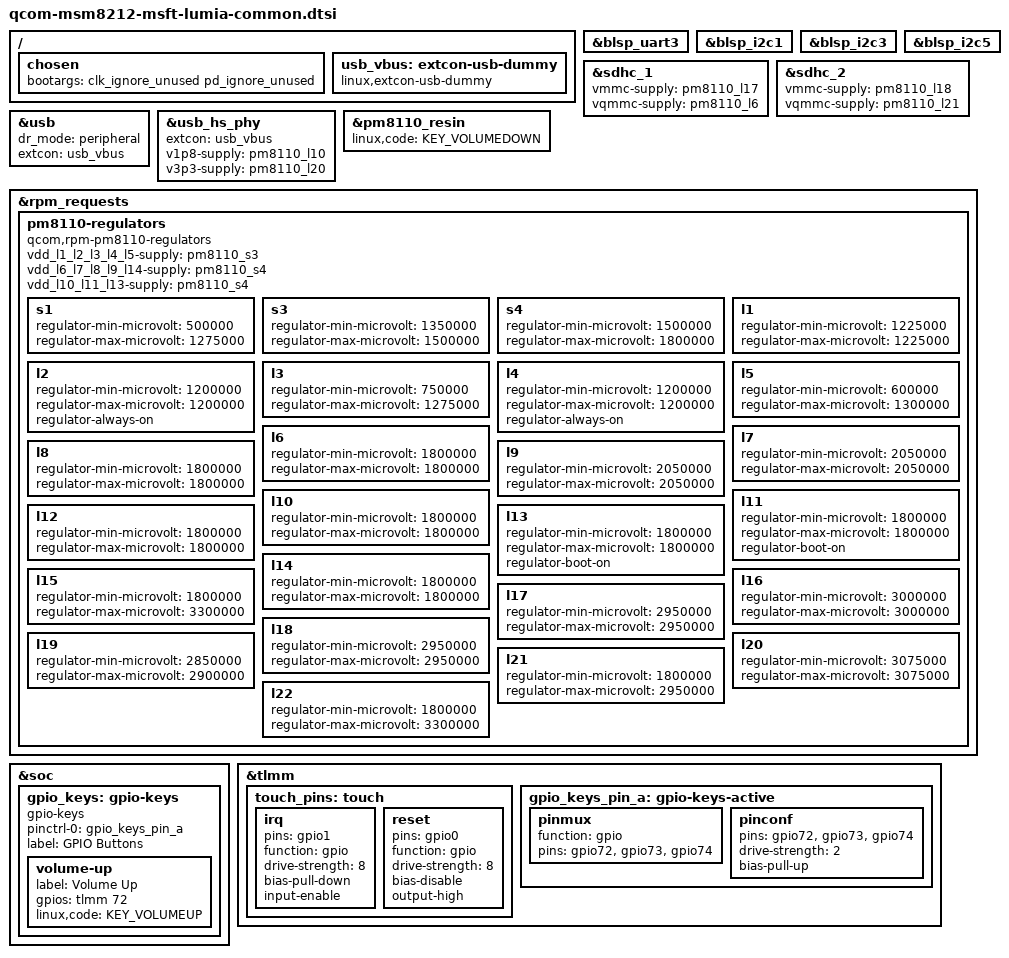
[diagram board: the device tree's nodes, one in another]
// SPDX-License-Identifier: BSD-3-Clause
/*
 * Common Board Device Tree for
 * Microsoft Mobile MSM8212 Platforms
 *
 * Copyright (c) 2021, Konrad Dybcio
 * Copyright (c) 2021, Ivaylo Ivanov <ivo.ivanov@null.net>
 */

#include "qcom-msm8212.dtsi"
#include "qcom-pm8110.dtsi"

/ {
	/*
	 * This prevents disabling unused clocks that should be on
	 */
	chosen {
		bootargs = "clk_ignore_unused pd_ignore_unused";

		#address-cells = <1>;
		#size-cells = <1>;
		ranges;
	};

	usb_vbus: extcon-usb-dummy {
		compatible = "linux,extcon-usb-dummy";
	};
};

&blsp_uart3 {
	status = "okay";
};

&blsp_i2c1 {
	status = "okay";

	/* Synaptics or Himax Touchscreen */
};

&blsp_i2c3 {
	status = "okay";
};

&blsp_i2c5 {
	status = "okay";
};

&sdhc_1 {
	status = "ok";

	vmmc-supply = <&pm8110_l17>;
	vqmmc-supply = <&pm8110_l6>;
};

&sdhc_2 {
	status = "ok";

	vmmc-supply = <&pm8110_l18>;
	vqmmc-supply = <&pm8110_l21>;
};

&usb {
	status = "okay";
	dr_mode = "peripheral";
	extcon = <&usb_vbus>;
};

&usb_hs_phy {
	extcon = <&usb_vbus>;

	v1p8-supply = <&pm8110_l10>;
	v3p3-supply = <&pm8110_l20>;
};

&pm8110_resin {
	status = "okay";
	linux,code = <KEY_VOLUMEDOWN>;
};

&rpm_requests {
	pm8110-regulators {
		compatible = "qcom,rpm-pm8110-regulators";
		vdd_l1_l2_l3_l4_l5-supply = <&pm8110_s3>;
		vdd_l6_l7_l8_l9_l14-supply = <&pm8110_s4>;
		vdd_l10_l11_l13-supply = <&pm8110_s4>;

		s1 {
			regulator-min-microvolt = <500000>;
			regulator-max-microvolt = <1275000>;
		};

		s3 {
			regulator-min-microvolt = <1350000>;
			regulator-max-microvolt = <1500000>;
		};

		s4 {
			regulator-min-microvolt = <1500000>;
			regulator-max-microvolt = <1800000>;
		};

		l1 {
			regulator-min-microvolt = <1225000>;
			regulator-max-microvolt = <1225000>;
		};

		l2 {
			// Powers up DDR. We don't want that off
			regulator-min-microvolt = <1200000>;
			regulator-max-microvolt = <1200000>;
			regulator-always-on;
		};

		l3 {
			regulator-min-microvolt = <750000>;
			regulator-max-microvolt = <1275000>;
		};

		l4 {
			regulator-min-microvolt = <1200000>;
			regulator-max-microvolt = <1200000>;
			regulator-always-on;
		};

		l5 {
			regulator-min-microvolt = <600000>;
			regulator-max-microvolt = <1300000>;
		};

		l6 {
			regulator-min-microvolt = <1800000>;
			regulator-max-microvolt = <1800000>;
		};

		l7 {
			regulator-min-microvolt = <2050000>;
			regulator-max-microvolt = <2050000>;
		};

		l8 {
			regulator-min-microvolt = <1800000>;
			regulator-max-microvolt = <1800000>;
		};

		l9 {
			regulator-min-microvolt = <2050000>;
			regulator-max-microvolt = <2050000>;
		};

		l10 {
			regulator-min-microvolt = <1800000>;
			regulator-max-microvolt = <1800000>;
		};

		l11 {
			regulator-min-microvolt = <1800000>;
			regulator-max-microvolt = <1800000>;
			regulator-boot-on;
		};

		l12 {
			regulator-min-microvolt = <1800000>;
			regulator-max-microvolt = <1800000>;
		};

		l13 {
			regulator-min-microvolt = <1800000>;
			regulator-max-microvolt = <1800000>;
			regulator-boot-on;
		};

		l14 {
			regulator-min-microvolt = <1800000>;
			regulator-max-microvolt = <1800000>;
		};

		l15 {
			regulator-min-microvolt = <1800000>;
			regulator-max-microvolt = <3300000>;
		};

		l16 {
			regulator-min-microvolt = <3000000>;
			regulator-max-microvolt = <3000000>;
		};

		l17 {
			regulator-min-microvolt = <2950000>;
			regulator-max-microvolt = <2950000>;
		};

		l18 {
			regulator-min-microvolt = <2950000>;
			regulator-max-microvolt = <2950000>;
		};

		l19 {
			regulator-min-microvolt = <2850000>;
			regulator-max-microvolt = <2900000>;
		};

		l20 {
			regulator-min-microvolt = <3075000>;
			regulator-max-microvolt = <3075000>;
		};

		l21 {
			regulator-min-microvolt = <1800000>;
			regulator-max-microvolt = <2950000>;
		};

		l22 {
			regulator-min-microvolt = <1800000>;
			regulator-max-microvolt = <3300000>;
		};
	};
};

&soc {
	gpio_keys: gpio-keys {
		compatible = "gpio-keys";

		pinctrl-names = "default";
		pinctrl-0 = <&gpio_keys_pin_a>;

		label = "GPIO Buttons";

		volume-up {
			label = "Volume Up";
			gpios = <&tlmm 72 GPIO_ACTIVE_HIGH>;
			linux,code = <KEY_VOLUMEUP>;
		};
	};
};

&tlmm {
	touch_pins: touch {
		irq {
			pins = "gpio1";
			function = "gpio";

			drive-strength = <8>;
			bias-pull-down;
			input-enable;
		};

		reset {
			pins = "gpio0";
			function = "gpio";

			drive-strength = <8>;
			bias-disable;
			output-high;
		};
	};

	gpio_keys_pin_a: gpio-keys-active {
		pinmux {
			function = "gpio";
			pins = "gpio72", "gpio73", "gpio74";
		};

		pinconf {
			pins = "gpio72", "gpio73", "gpio74";
			drive-strength = <2>;
			bias-pull-up;
		};
	};
};
